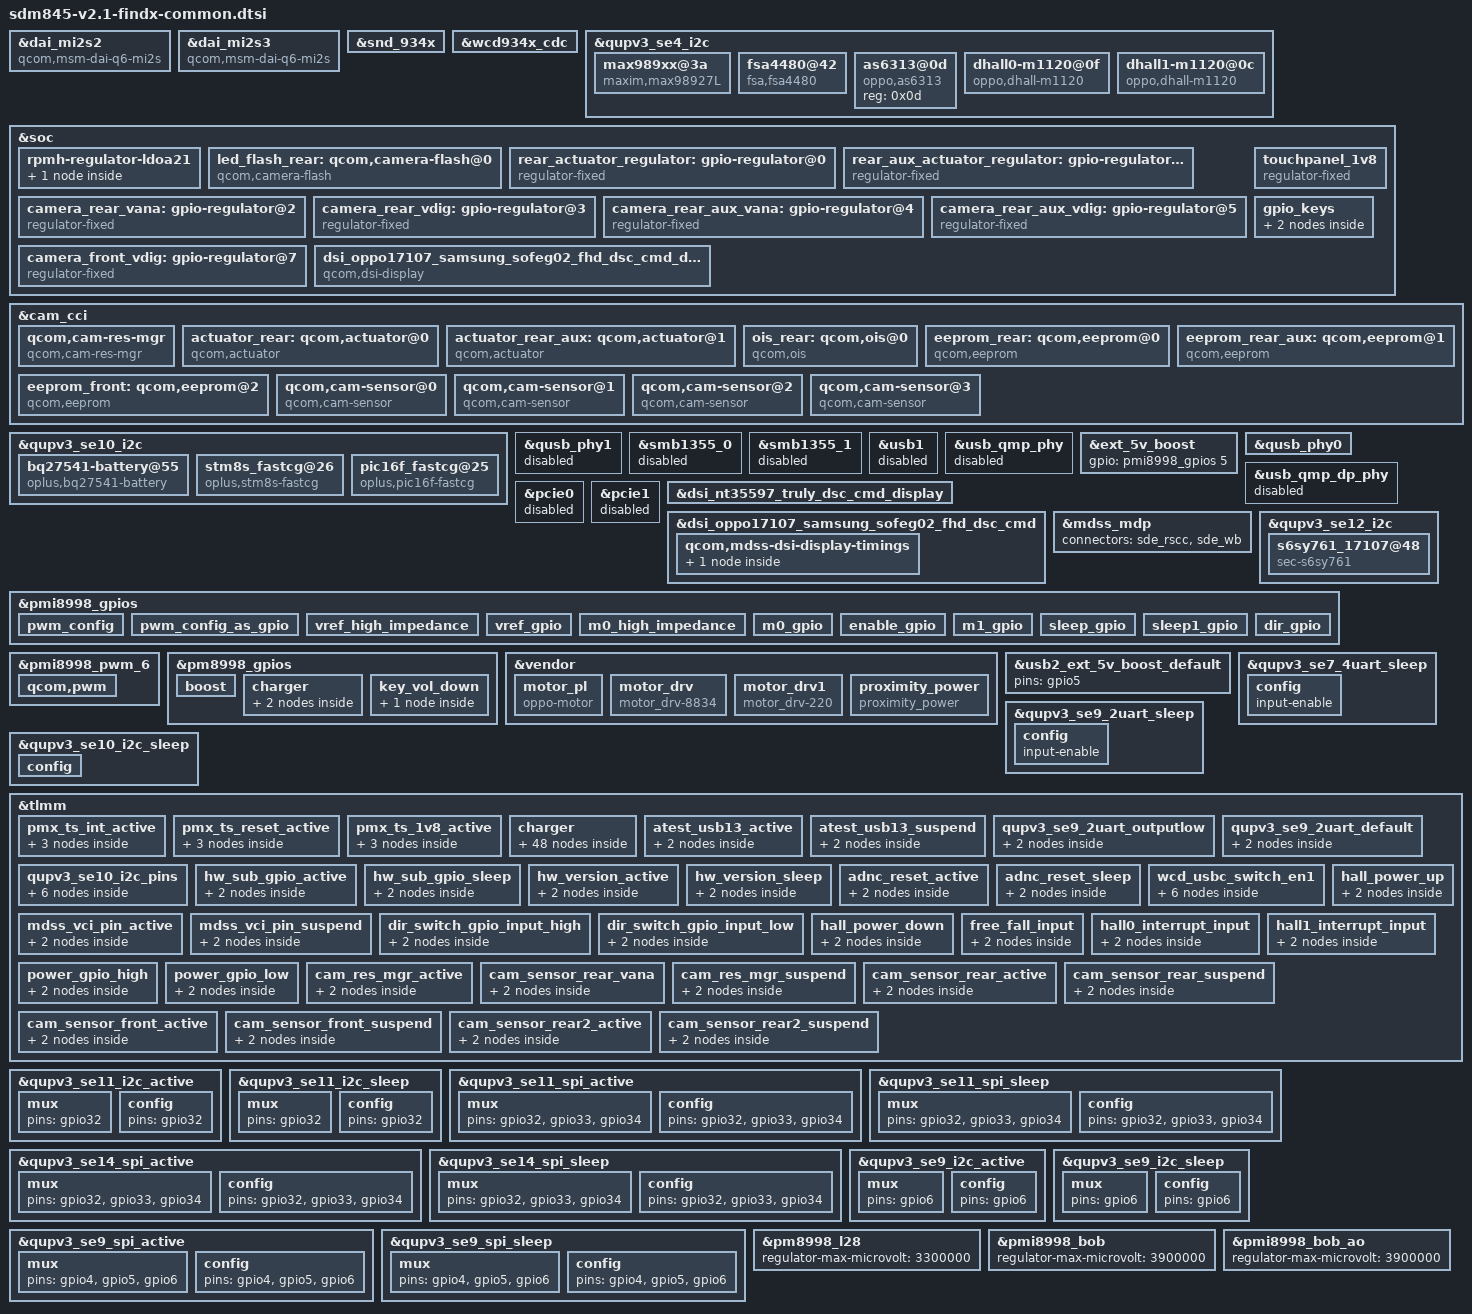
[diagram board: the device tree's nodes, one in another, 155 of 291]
/* Copyright (c) 2016-2017, The Linux Foundation. All rights reserved.
 *
 * This program is free software; you can redistribute it and/or modify
 * it under the terms of the GNU General Public License version 2 and
 * only version 2 as published by the Free Software Foundation.
 *
 * This program is distributed in the hope that it will be useful,
 * but WITHOUT ANY WARRANTY; without even the implied warranty of
 * MERCHANTABILITY or FITNESS FOR A PARTICULAR PURPOSE.  See the
 * GNU General Public License for more details.
 */

#include "dsi-panel-dsi_oppo17107_samsung_sofeg02_fhd_dsc_cmd.dtsi"

/* Audio */
&dai_mi2s2 {
    compatible = "qcom,msm-dai-q6-mi2s";
    qcom,msm-dai-q6-mi2s-dev-id = <2>;
    qcom,msm-mi2s-rx-lines = <2>;
    qcom,msm-mi2s-tx-lines = <1>;
    pinctrl-names = "default", "sleep";
    pinctrl-0 = <&tert_mi2s_active
            &tert_mi2s_sd0_active
            &tert_mi2s_sd1_active>;
    pinctrl-1 = <&tert_mi2s_sleep
            &tert_mi2s_sd0_sleep
            &tert_mi2s_sd1_sleep>;
};

&dai_mi2s3 {
    compatible = "qcom,msm-dai-q6-mi2s";
    qcom,msm-dai-q6-mi2s-dev-id = <3>;
    qcom,msm-mi2s-rx-lines = <2>;
    qcom,msm-mi2s-tx-lines = <1>;
    pinctrl-names = "default", "sleep";
    pinctrl-0 = <&quat_mi2s_active
            &quat_mi2s_sd0_active
            &quat_mi2s_sd1_active>;
    pinctrl-1 = <&quat_mi2s_sleep
            &quat_mi2s_sd0_sleep
            &quat_mi2s_sd1_sleep>;
};

&snd_934x {
	qcom,msm-mbhc-hs-mic-max-threshold-mv = <2600>;
	qcom,msm-mbhc-hs-mic-min-threshold-mv = <75>;
};

&wcd934x_cdc {
    qcom,cdc-micbias1-mv = <1800>;
    qcom,cdc-micbias2-mv = <2700>;
    qcom,cdc-micbias3-mv = <1800>;
    qcom,cdc-micbias4-mv = <2850>;
};

&qupv3_se4_i2c {
	status = "ok";

	max989xx@3a {
		compatible = "maxim,max98927L";
		reg = <0x3a>;
		mono_stereo_mode = <0>;
		interleave_mode = <0>;
		maxim,98927-reset-gpio = <&tlmm 69 0x00>;
		max989xx_vdd-supply = <&pm8998_s4>;
		status = "okay";
	};
};

&qupv3_se4_i2c {
	status = "ok";
	fsa4480@42 {
		compatible = "fsa,fsa4480";
		reg = <0x42>;
		interrupts = <52 0>;
		oppo,fsa4480-irq = <&tlmm 52 0x00>;
		interrupt-names = "fsa4480_irq";
		status = "okay";
	};
};

&qupv3_se4_i2c {
	status = "ok";
	as6313@0d {
		compatible = "oppo,as6313";
		reg = <0x0d>;
		status = "okay";
	};
};

/* Camera */
&soc {
	/delete-node/ qupv3_se2_i2c;
	/delete-node/ qupv3_se2_spi;

	rpmh-regulator-ldoa21 {
		pm8998_l21: regulator-l21 {
			regulator-min-microvolt = <2850000>;
		};
	};

	led_flash_rear: qcom,camera-flash@0 {
		cell-index = <0>;
		reg = <0x00 0x00>;
		compatible = "qcom,camera-flash";
		qcom,flash-name = "pmic";
		flash-source = <&pmi8998_flash0>;
		torch-source = <&pmi8998_torch0>;
		switch-source = <&pmi8998_switch0>;
		status = "ok";
	};

	rear_actuator_regulator: gpio-regulator@0 {
		compatible = "regulator-fixed";
		reg = <0x00 0x00>;
		regulator-name = "rear_actuator_regulator";
		regulator-min-microvolt = <2800000>;
		regulator-max-microvolt = <2800000>;
		regulator-enable-ramp-delay = <100>;
		enable-active-high;
		vin-supply = <&pmi8998_bob>;
	};

	rear_aux_actuator_regulator: gpio-regulator@1 {
		compatible = "regulator-fixed";
		reg = <0x01 0x00>;
		regulator-name = "rear_aux_actuator_regulator";
		regulator-min-microvolt = <2800000>;
		regulator-max-microvolt = <2800000>;
		regulator-enable-ramp-delay = <100>;
		enable-active-high;
		vin-supply = <&pmi8998_bob>;
	};

	camera_rear_vana: gpio-regulator@2 {
		compatible = "regulator-fixed";
		reg = <0x02 0x00>;
		regulator-name = "camera_rear_vana";
		regulator-min-microvolt = <2800000>;
		regulator-max-microvolt = <2800000>;
		regulator-enable-ramp-delay = <135>;
		enable-active-high;
		gpio = <&tlmm 27 0>;
		pinctrl-names = "default";
		pinctrl-0 = <&cam_sensor_rear_vana>;
		vin-supply = <&pmi8998_bob>;
	};

	camera_rear_vdig: gpio-regulator@3 {
		compatible = "regulator-fixed";
		reg = <0x03 0x00>;
		regulator-name = "camera_rear_vdig";
		regulator-min-microvolt = <1050000>;
		regulator-max-microvolt = <1050000>;
		regulator-enable-ramp-delay = <135>;
		enable-active-high;
		gpio = <&tlmm 8 0>;
		vin-supply = <&pmi8998_bob &pm8998_s3>;
	};

	camera_rear_aux_vana: gpio-regulator@4 {
		compatible = "regulator-fixed";
		reg = <0x04 0x00>;
		regulator-name = "camera_rear_aux_vana";
		regulator-min-microvolt = <2800000>;
		regulator-max-microvolt = <2800000>;
		regulator-enable-ramp-delay = <135>;
		enable-active-high;
		gpio = <&tlmm 82 0>;
		vin-supply = <&pmi8998_bob>;
	};

	camera_rear_aux_vdig: gpio-regulator@5 {
		compatible = "regulator-fixed";
		reg = <0x05 0x00>;
		regulator-name = "camera_rear_aux_vdig";
		regulator-min-microvolt = <1050000>;
		regulator-max-microvolt = <1050000>;
		regulator-enable-ramp-delay = <135>;
		enable-active-high;
		gpio = <&tlmm 79 0>;
		vin-supply = <&pmi8998_bob &pm8998_s3>;
	};

	camera_front_vdig: gpio-regulator@7 {
		compatible = "regulator-fixed";
		reg = <0x07 0x00>;
		regulator-name = "camera_front_vdig";
		regulator-min-microvolt = <1050000>;
		regulator-max-microvolt = <1050000>;
		regulator-enable-ramp-delay = <135>;
		enable-active-high;
		gpio = <&tlmm 117 0>;
		vin-supply = <&pmi8998_bob &pm8998_s3>;
	};
};

&cam_cci {
	qcom,cam-res-mgr {
		compatible = "qcom,cam-res-mgr";
		status = "ok";
		shared-gpios = <122 8>;
		pinctrl-names = "cam_res_mgr_default", "cam_res_mgr_suspend";
		pinctrl-0 = <&cam_res_mgr_active>;
		pinctrl-1 = <&cam_res_mgr_suspend>;
	};

	actuator_rear: qcom,actuator@0 {
		cell-index = <0>;
		reg = <0x0>;
		compatible = "qcom,actuator";
		cci-master = <0>;
		cam_vaf-supply = <&rear_actuator_regulator>;
		regulator-names = "cam_vaf";
		rgltr-cntrl-support;
		rgltr-min-voltage = <2800000>;
		rgltr-max-voltage = <2800000>;
		rgltr-load-current = <0>;
		gpios = <&tlmm 122 0>;
		gpio-vaf = <0>;
		gpio-req-tbl-num = <0>;
		gpio-req-tbl-flags = <0>;
		gpio-req-tbl-label = "CAM_VAF";
	};

	actuator_rear_aux: qcom,actuator@1 {
		cell-index = <1>;
		reg = <0x1>;
		compatible = "qcom,actuator";
		cci-master = <1>;
		cam_vaf-supply = <&rear_aux_actuator_regulator>;
		regulator-names = "cam_vaf";
		rgltr-cntrl-support;
		rgltr-min-voltage = <2800000>;
		rgltr-max-voltage = <2800000>;
		rgltr-load-current = <0>;
		gpios = <&tlmm 122 0>;
		gpio-vaf = <0>;
		gpio-req-tbl-num = <0>;
		gpio-req-tbl-flags = <0>;
		gpio-req-tbl-label = "CAM_VAF";
	};

	ois_rear: qcom,ois@0 {
		cell-index = <0>;
		reg = <0x0>;
		compatible = "qcom,ois";
		cci-master = <0>;
		status = "ok";
	};

	eeprom_rear: qcom,eeprom@0 {
		cell-index = <0>;
		reg = <0>;
		compatible = "qcom,eeprom";
		cam_vana-supply = <&camera_rear_vana>;
		cam_vdig-supply = <&camera_rear_vdig>;
		//cam_vio-supply = <&pm8998_lvs1>;
		cam_clk-supply = <&titan_top_gdsc>;
		regulator-names = "cam_clk", "cam_vana", "cam_vdig";
		rgltr-cntrl-support;
		rgltr-min-voltage = <0 2800000 1050000>;
		rgltr-max-voltage = <0 2800000 1050000>;
		rgltr-load-current = <0 0 0>;
		gpio-no-mux = <0>;
		pinctrl-names = "cam_default", "cam_suspend";
		pinctrl-0 = <&cam_sensor_mclk0_active
				&cam_sensor_rear_active>;
		pinctrl-1 = <&cam_sensor_mclk0_suspend
				&cam_sensor_rear_suspend>;
		gpios = <&tlmm 13 0>,
			<&tlmm 28 0>;
		gpio-reset = <1>;
		gpio-req-tbl-num = <0 1>;
		gpio-req-tbl-flags = <1 0>;
		gpio-req-tbl-label = "CAMIF_MCLK0",
					"CAM_RESET0";
		sensor-position = <0>;
		sensor-mode = <0>;
		cci-master = <0>;
		status = "ok";
		clocks = <&clock_camcc CAM_CC_MCLK0_CLK>;
		clock-names = "cam_clk";
		clock-cntl-level = "turbo";
		clock-rates = <24000000>;
	};

	eeprom_rear_aux: qcom,eeprom@1 {
		cell-index = <1>;
		reg = <0x1>;
		compatible = "qcom,eeprom";
		cam_vana-supply = <&camera_rear_aux_vana>;
		cam_vdig-supply = <&camera_rear_aux_vdig>;
		//cam_vio-supply = <&pm8998_lvs1>;
		cam_clk-supply = <&titan_top_gdsc>;
		regulator-names = "cam_clk", "cam_vana", "cam_vdig";
		rgltr-cntrl-support;
		rgltr-min-voltage = <0 2800000 1050000>;
		rgltr-max-voltage = <0 2800000 1050000>;
		rgltr-load-current = <0 0 0>;
		gpio-no-mux = <0>;
		pinctrl-names = "cam_default", "cam_suspend";
		pinctrl-0 = <&cam_sensor_mclk2_active
				 &cam_sensor_rear2_active>;
		pinctrl-1 = <&cam_sensor_mclk2_suspend
				 &cam_sensor_rear2_suspend>;
		gpios = <&tlmm 15 0>,
			<&tlmm 23 0>;
		gpio-reset = <1>;
		gpio-req-tbl-num = <0 1>;
		gpio-req-tbl-flags = <1 0>;
		gpio-req-tbl-label = "CAMIF_MCLK1",
					"CAM_RESET1";
		sensor-position = <0>;
		sensor-mode = <0>;
		cci-master = <1>;
		status = "ok";
		clocks = <&clock_camcc CAM_CC_MCLK2_CLK>;
		clock-names = "cam_clk";
		clock-cntl-level = "turbo";
		clock-rates = <24000000>;
	};

	eeprom_front: qcom,eeprom@2 {
		cell-index = <2>;
		reg = <0x2>;
		compatible = "qcom,eeprom";
		cam_vana-supply = <&camera_rear_vana>;
		cam_vdig-supply = <&camera_front_vdig>;
		//cam_vio-supply = <&pm8998_lvs1>;
		cam_clk-supply = <&titan_top_gdsc>;
		regulator-names = "cam_clk", "cam_vana", "cam_vdig";
		rgltr-cntrl-support;
		rgltr-min-voltage = <0 2800000 1050000>;
		rgltr-max-voltage = <0 2800000 1050000>;
		rgltr-load-current = <0 0 0>;
		gpio-no-mux = <0>;
		pinctrl-names = "cam_default", "cam_suspend";
		pinctrl-0 = <&cam_sensor_mclk1_active
				 &cam_sensor_front_active>;
		pinctrl-1 = <&cam_sensor_mclk1_suspend
				 &cam_sensor_front_suspend>;
		gpios = <&tlmm 14 0>,
			<&tlmm 9 0>;
		gpio-reset = <1>;
		gpio-req-tbl-num = <0 1>;
		gpio-req-tbl-flags = <1 0>;
		gpio-req-tbl-label = "CAMIF_MCLK2",
					"CAM_RESET2";
		sensor-position = <1>;
		sensor-mode = <0>;
		cci-master = <0>;
		status = "ok";
		clocks = <&clock_camcc CAM_CC_MCLK1_CLK>;
		clock-names = "cam_clk";
		clock-cntl-level = "turbo";
		clock-rates = <24000000>;
	};

	qcom,cam-sensor@0 {
		cell-index = <0>;
		compatible = "qcom,cam-sensor";
		reg = <0x0>;
		csiphy-sd-index = <0>;
		sensor-position-roll = <270>;
		sensor-position-pitch = <0>;
		sensor-position-yaw = <180>;
		led-flash-src = <&led_flash_rear>;
		actuator-src = <&actuator_rear>;
		ois-src = <&ois_rear>;
		eeprom-src = <&eeprom_rear>;
		cam_vana-supply = <&camera_rear_vana>;
		cam_vdig-supply = <&camera_rear_vdig>;
		//cam_vio-supply = <&pm8998_lvs1>;
		cam_v_custom1-supply = <&pm8998_l21>;
		cam_clk-supply = <&titan_top_gdsc>;
		regulator-names = "cam_clk", "cam_vana", "cam_vdig", "cam_v_custom1";
		rgltr-cntrl-support;
		rgltr-min-voltage = <0 2800000 1050000 2850000>;
		rgltr-max-voltage = <0 2800000 1050000 2850000>;
		rgltr-load-current = <0 0 0 800000>;
		gpio-no-mux = <0>;
		pinctrl-names = "cam_default", "cam_suspend";
		pinctrl-0 = <&cam_sensor_mclk0_active
				&cam_sensor_rear_active>;
		pinctrl-1 = <&cam_sensor_mclk0_suspend
				&cam_sensor_rear_suspend>;
		gpios = <&tlmm 13 0>,
			<&tlmm 28 0>;
		gpio-reset = <1>;
		gpio-req-tbl-num = <0 1>;
		gpio-req-tbl-flags = <1 0>;
		gpio-req-tbl-label = "CAMIF_MCLK0",
					"CAM_RESET0";
		sensor-mode = <0>;
		cci-master = <0>;
		status = "ok";
		clocks = <&clock_camcc CAM_CC_MCLK0_CLK>;
		clock-names = "cam_clk";
		clock-cntl-level = "turbo";
		clock-rates = <24000000>;
	};

	qcom,cam-sensor@1 {
		cell-index = <1>;
		compatible = "qcom,cam-sensor";
		reg = <0x1>;
		csiphy-sd-index = <1>;
		sensor-position-roll = <270>;
		sensor-position-pitch = <0>;
		sensor-position-yaw = <180>;
		actuator-src = <&actuator_rear_aux>;
		led-flash-src = <&led_flash_rear>;
		eeprom-src = <&eeprom_rear_aux>;
		cam_vana-supply = <&camera_rear_aux_vana>;
		cam_vdig-supply = <&camera_rear_aux_vdig>;
		//cam_vio-supply = <&pm8998_lvs1>;
		cam_clk-supply = <&titan_top_gdsc>;
		regulator-names = "cam_clk", "cam_vana", "cam_vdig";
		rgltr-cntrl-support;
		rgltr-min-voltage = <0 2800000 1050000>;
		rgltr-max-voltage = <0 2800000 1050000>;
		rgltr-load-current = <0 0 0>;
		gpio-no-mux = <0>;
		pinctrl-names = "cam_default", "cam_suspend";
		pinctrl-0 = <&cam_sensor_mclk2_active
				&cam_sensor_rear2_active>;
		pinctrl-1 = <&cam_sensor_mclk2_suspend
				&cam_sensor_rear2_suspend>;
		gpios = <&tlmm 15 0>,
			<&tlmm 23 0>;
		gpio-reset = <1>;
		gpio-req-tbl-num = <0 1>;
		gpio-req-tbl-flags = <1 0>;
		gpio-req-tbl-label = "CAMIF_MCLK1",
					"CAM_RESET1";
		sensor-mode = <0>;
		cci-master = <1>;
		status = "ok";
		clocks = <&clock_camcc CAM_CC_MCLK2_CLK>;
		clock-names = "cam_clk";
		clock-cntl-level = "turbo";
		clock-rates = <24000000>;
	};

	qcom,cam-sensor@2 {
		cell-index = <2>;
		compatible = "qcom,cam-sensor";
		reg = <0x02>;
		csiphy-sd-index = <2>;
		sensor-position-roll = <270>;
		sensor-position-pitch = <0>;
		sensor-position-yaw = <0>;
		eeprom-src = <&eeprom_front>;
		/*
		actuator-src = <&actuator_front>;
		led-flash-src = <&led_flash_front>;
		*/
		cam_vana-supply = <&camera_rear_vana>;
		cam_vdig-supply = <&camera_front_vdig>;
		//cam_vio-supply = <&pm8998_lvs1>;
		cam_clk-supply = <&titan_top_gdsc>;
		regulator-names = "cam_clk", "cam_vana", "cam_vdig";
		rgltr-cntrl-support;
		rgltr-min-voltage = <0 2800000 1050000>;
		rgltr-max-voltage = <0 2800000 1050000>;
		rgltr-load-current = <0 0 0>;
		gpio-no-mux = <0>;
		pinctrl-names = "cam_default", "cam_suspend";
		pinctrl-0 = <&cam_sensor_mclk1_active
				 &cam_sensor_front_active>;
		pinctrl-1 = <&cam_sensor_mclk1_suspend
				 &cam_sensor_front_suspend>;
		gpios = <&tlmm 14 0>,
			<&tlmm 9 0>;
		gpio-reset = <1>;
		gpio-req-tbl-num = <0 1>;
		gpio-req-tbl-flags = <1 0>;
		gpio-req-tbl-label = "CAMIF_MCLK2",
					"CAM_RESET2";
		sensor-mode = <0>;
		cci-master = <0>;
		status = "ok";
		clocks = <&clock_camcc CAM_CC_MCLK1_CLK>;
		clock-names = "cam_clk";
		clock-cntl-level = "turbo";
		clock-rates = <24000000>;
	};

	qcom,cam-sensor@3 {
		cell-index = <3>;
		compatible = "qcom,cam-sensor";
		reg = <0x03>;
		csiphy-sd-index = <3>;
		sensor-position-roll = <270>;
		sensor-position-pitch = <0>;
		sensor-position-yaw = <0>;
		gpio-no-mux = <0>;
		sensor-mode = <0>;
		cci-master = <1>;
		status = "ok";
	};
};

/* Charger */
&qupv3_se10_i2c {
	pinctrl-names = "default", "sleep", "pulldown", "pullup";
	pinctrl-2 = <&qupv3_se10_i2c_pulldown>;
	pinctrl-3 = <&qupv3_se10_i2c_pullup>;

	bq27541-battery@55 {
		status = "okay";
		compatible = "oplus,bq27541-battery";
		reg = <0x55>;
		qcom,modify-soc-smooth;
	};

	stm8s_fastcg@26{
		status = "okay";
		compatible = "oplus,stm8s-fastcg";
		reg = <0x26>;
		qcom,oplus_batt_4400mv;
		qcom,vooc_fw_update_newmethod;
		qcom,vooc-fw-type = <5>;
		qcom,vooc-low-temp = <120>;
		qcom,vooc-high-temp = <430>;
		qcom,vooc-low-soc = <1>;
		qcom,vooc-high-soc = <85>;

		pinctrl-names = "switch1_act_switch2_act", "switch1_sleep_switch2_sleep",
						"switch1_act_switch3_act", "switch1_sleep_switch3_sleep",
						"switch1_act_switch2_sleep", "switch1_sleep_switch2_act",
						"clock_active","clock_sleep",
						"data_active","data_sleep",
						"reset_active","reset_sleep";
		pinctrl-0 = <&charging_switch1_active>;
		pinctrl-1 = <&charging_switch1_sleep >;
		pinctrl-2 = <&charging_switch1_active>;
		pinctrl-3 = <&charging_switch1_sleep >;
		pinctrl-4 = <&charging_switch1_active>;
		pinctrl-5 = <&charging_switch1_sleep>;
		pinctrl-6 = <&charging_clock_active >;
		pinctrl-7 = <&charging_clock_sleep >;
		pinctrl-8 = <&charging_data_active >;
		pinctrl-9 = <&charging_data_sleep >;
		pinctrl-10 = <&charging_reset_active >;
		pinctrl-11 = <&charging_reset_sleep >;

		qcom,charging_switch1-gpio = <&tlmm 51 0x00>;
		//qcom,charging_switch2-gpio = <&tlmm 113 0x00>;
		//qcom,charging_switch3-gpio = <&tlmm 38 0x00>;

		qcom,charging_reset-gpio = <&tlmm 102 0x00>;
		qcom,charging_clock-gpio = <&tlmm 43 0x00>;
		qcom,charging_data-gpio = <&tlmm 44 0x00>;
	};

	pic16f_fastcg@25{
		status = "okay";
		compatible = "oplus,pic16f-fastcg";
		reg = <0x25>;

		pinctrl-names = "switch1_act_switch2_act", "switch1_sleep_switch2_sleep",
						"switch1_act_switch3_act", "switch1_sleep_switch3_sleep",
						"switch1_act_switch2_sleep", "switch1_sleep_switch2_act",
						"clock_active","clock_sleep",
						"data_active","data_sleep",
						"reset_active","reset_sleep";
		pinctrl-0 = <&charging_switch1_active>;
		pinctrl-1 = <&charging_switch1_sleep >;
		pinctrl-2 = <&charging_switch1_active>;
		pinctrl-3 = <&charging_switch1_sleep >;
		pinctrl-4 = <&charging_switch1_active>;
		pinctrl-5 = <&charging_switch1_sleep>;
		pinctrl-6 = <&charging_clock_active >;
		pinctrl-7 = <&charging_clock_sleep >;
		pinctrl-8 = <&charging_data_active >;
		pinctrl-9 = <&charging_data_sleep >;
		pinctrl-10 = <&charging_reset_active >;
		pinctrl-11 = <&charging_reset_sleep >;

		qcom,charging_switch1-gpio = <&tlmm 51 0x00>;
		//qcom,charging_switch2-gpio = <&tlmm 113 0x00>;
		//qcom,charging_switch3-gpio = <&tlmm 38 0x00>;

		qcom,charging_reset-gpio = <&tlmm 102 0x00>;
		qcom,charging_clock-gpio = <&tlmm 43 0x00>;
		qcom,charging_data-gpio = <&tlmm 44 0x00>;
	};
};

&qusb_phy1 {
	status = "disabled";
};

&smb1355_0 {
	status = "disabled";
};

&smb1355_1 {
	status = "disabled";
};

&usb1 {
	status = "disabled";
};

&usb_qmp_phy {
	status = "disabled";
};

&ext_5v_boost {
	gpio = <&pmi8998_gpios 5 GPIO_ACTIVE_HIGH>;
};

&qusb_phy0 {
	qcom,qusb-phy-init-seq =
		/* <value reg_offset> */
		<0x23 0x210 /* PWR_CTRL1 */
		0x03 0x04  /* PLL_ANALOG_CONTROLS_TWO */
		0x7c 0x18c /* PLL_CLOCK_INVERTERS */
		0x80 0x2c  /* PLL_CMODE */
		0x0a 0x184 /* PLL_LOCK_DELAY */
		0x19 0xb4  /* PLL_DIGITAL_TIMERS_TWO */
		0x40 0x194 /* PLL_BIAS_CONTROL_1 */
		//0x20 0x198 /* PLL_BIAS_CONTROL_2 */
		0x1e 0x198 /* PLL_BIAS_CONTROL_2 */
		0x21 0x214 /* PWR_CTRL2 */
		0x08 0x220 /* IMP_CTRL1 */
		0x58 0x224 /* IMP_CTRL2 */
		//0x45 0x240 /* TUNE1 */
		0x42 0x240 /* TUNE1 */
		0x29 0x244 /* TUNE2 */
		0xca 0x248 /* TUNE3 */
		0x04 0x24c /* TUNE4 */
		0x03 0x250 /* TUNE5 */
		0x00 0x23c /* CHG_CTRL2 */
		0x22 0x210>; /* PWR_CTRL1 */
	qcom,qusb-phy-init-seq-new =
		/* <value reg_offset> */
		<0x23 0x210 /* PWR_CTRL1 */
		0x03 0x04  /* PLL_ANALOG_CONTROLS_TWO */
		0x7c 0x18c /* PLL_CLOCK_INVERTERS */
		0x80 0x2c  /* PLL_CMODE */
		0x0a 0x184 /* PLL_LOCK_DELAY */
		0x19 0xb4  /* PLL_DIGITAL_TIMERS_TWO */
		0x40 0x194 /* PLL_BIAS_CONTROL_1 */
		//0x20 0x198 /* PLL_BIAS_CONTROL_2 */
		0x1a 0x198 /* PLL_BIAS_CONTROL_2 */
		0x21 0x214 /* PWR_CTRL2 */
		0x08 0x220 /* IMP_CTRL1 */
		0x58 0x224 /* IMP_CTRL2 */
		//0x45 0x240 /* TUNE1 */
		0x43 0x240 /* TUNE1 */
		0x29 0x244 /* TUNE2 */
		0xca 0x248 /* TUNE3 */
		0x04 0x24c /* TUNE4 */
		0x03 0x250 /* TUNE5 */
		0x00 0x23c /* CHG_CTRL2 */
		0x22 0x210>; /* PWR_CTRL1 */
	qcom,qusb-phy-oppo-host-init-seq =
		/* <value reg_offset> */
		<0x23 0x210 /* PWR_CTRL1 */
		0x03 0x04  /* PLL_ANALOG_CONTROLS_TWO */
		0x7c 0x18c /* PLL_CLOCK_INVERTERS */
		0x80 0x2c  /* PLL_CMODE */
		0x0a 0x184 /* PLL_LOCK_DELAY */
		0x19 0xb4  /* PLL_DIGITAL_TIMERS_TWO */
		0x40 0x194 /* PLL_BIAS_CONTROL_1 */
		0x1e 0x198 /* PLL_BIAS_CONTROL_2 */
		0x21 0x214 /* PWR_CTRL2 */
		0x07 0x220 /* IMP_CTRL1 */
		0x58 0x224 /* IMP_CTRL2 */
		0x46 0x240 /* TUNE1 */
		0x2b 0x244 /* TUNE2 */
		0xca 0x248 /* TUNE3 */
		0x04 0x24c /* TUNE4 */
		0x03 0x250 /* TUNE5 */
		0x00 0x23c /* CHG_CTRL2 */
		0x22 0x210>; /* PWR_CTRL1 */
};

&usb_qmp_dp_phy {
	status = "disabled";
};

&pcie0 {
	status = "disabled";
};

&pcie1 {
	status = "disabled";
};

/* Display */
&dsi_nt35597_truly_dsc_cmd_display {
	/delete-property/ qcom,dsi-display-active;
};

&dsi_oppo17107_samsung_sofeg02_fhd_dsc_cmd{
	qcom,dsi-display-active;
};

&dsi_oppo17107_samsung_sofeg02_fhd_dsc_cmd{
	qcom,panel-supply-entries = <&dsi_panel_pwr_supply_no_labibb>;
	qcom,panel-supply-oppo-hardware-march = <&dsi_panel_pwr_supply_vdd_no_labibb>;

	qcom,mdss-dsi-bl-min-level = <1>;
	qcom,mdss-dsi-mode-sel-gpio-state = "single_port";
	qcom,panel-mode-gpio = <&tlmm 52 0>;
	qcom,platform-te-gpio = <&tlmm 10 0>;
	qcom,platform-reset-gpio = <&tlmm 6 0>;
	qcom,platform-vci-control-gpio = <&tlmm 26 0>;
};

&mdss_mdp {
	connectors = <&sde_rscc &sde_wb>;
};

&dsi_oppo17107_samsung_sofeg02_fhd_dsc_cmd {
	qcom,mdss-dsi-t-clk-post = <0x11>;
	qcom,mdss-dsi-t-clk-pre =  <0x34>;
	qcom,mdss-dsi-display-timings {
		timing@0{
			qcom,mdss-dsi-panel-phy-timings = [00 14 05 05 1F 0A 05
				05 03 03 04 00];
			qcom,display-topology = <1 1 1>,
						<2 2 1>, /* dsc merge */
						<2 1 1>; /* 3d mux */
			qcom,default-topology-index = <1>;
		};
	};
};

&soc {
	dsi_oppo17107_samsung_sofeg02_fhd_dsc_cmd_display: qcom,dsi-display@1 {
		compatible = "qcom,dsi-display";
		label = "dsi_oppo17107_samsung_sofeg02_fhd_dsc_cmd_display";
		qcom,display-type = "primary";

		qcom,dsi-ctrl = <&mdss_dsi0>;
		qcom,dsi-phy = <&mdss_dsi_phy0>;
		clocks = <&mdss_dsi0_pll BYTECLK_MUX_0_CLK>,
			<&mdss_dsi0_pll PCLK_MUX_0_CLK>;
		clock-names = "mux_byte_clk", "mux_pixel_clk";

		pinctrl-names = "panel_active", "panel_suspend";
		pinctrl-0 = <&sde_dsi_active &sde_te_active  &mdss_vci_pin_active>;
		pinctrl-1 = <&sde_dsi_suspend &sde_te_suspend  &mdss_vci_pin_suspend>;
		qcom,platform-te-gpio = <&tlmm 10 0>;
		qcom,platform-reset-gpio = <&tlmm 6 0>;
		qcom,platform-vci-control-gpio = <&tlmm 26 0>;
		//qcom,platform-poc-control-gpio = <&tlmm 25 0>;

		qcom,dsi-panel = <&dsi_oppo17107_samsung_sofeg02_fhd_dsc_cmd>;

		vddio-supply = <&pm8998_l14>;
		vdd-supply = <&pm8998_l28>;
	};
};

/* Touchscreen */
&qupv3_se12_i2c {
	status = "okay";
	s6sy761_17107@48 {
		compatible = "sec-s6sy761";
		reg = <0x48>;
		chip-name = "S6SY761";

		/* Interrupt && Irq-gpio */
		interrupt-parent = <&tlmm>;
		interrupts = <125 0x2008>;

		/* Power Config */
		enable2v8_gpio = <&tlmm 26 0x1>;
		// enable1v8_gpio = <&tlmm 32 0x1>;
		vdd_2v8-supply = <&pm8998_l28>;
		vcc_1v8-supply = <&touchpanel_1v8>;
		vdd_2v8_volt = <3300000>;

		/* Other HW Resource */
		irq-gpio = <&tlmm 125 0x2008>;
		reset-gpio = <&tlmm 99 0x1>;
		pinctrl-names = "default";
		pinctrl-0 = <&ts_int_active &ts_reset_active &ts_1v8_active>;

		touchpanel,max-num-support = <10>;
		touchpanel,tx-rx-num = <17 37>;
		earsense,tx-rx-num = <17 18>;
		touchpanel,panel-coords = <1080 2340>;
		touchpanel,display-coords = <1080 2340>;
		touchpanel,touchmajor-limit = <32 54>;

		/* SW Support Feature Control */
		ear_sense_support;
		black_gesture_support;
		fw_edge_limit_support;
		charger_pump_support;
		// spurious_fingerprint_support;
		fw_update_app_support;
		smart_gesture_support;
		game_switch_support;
		kernel_grip_support_special;
		auto_test_need_cal_support;

		/*
		 * Virtual Key Config:
		 * 1:touchpanel,button-type: <virtualkey_type  supportted_button-map>
		 * virtualkey_type:
		 * Type 1: using board_properties
		 * Type 2: using same IC (button zone&& touch zone are seprate)
		 * Type 3: using diffrent IC (button zone&& touch zone are seprate)
		 * Type 4: No need of virtual key process
		 * supportted_button-map:select|menu|home|back
		 *
		 * 2:touchpanel,button-map
		 * type (X1,Y1)(X2,Y2)(X3,Y3)(Width_X,Hight_Y)--Only when button-type is 0
		 */
		touchpanel,button-type = <4>;
		touchpanel.button-TRx = <0 0>;
	};
};

&soc {
	touchpanel_1v8: touchpanel_1v8 {
		compatible = "regulator-fixed";
		regulator-name = "touchpanel_1v8";
		startup-delay-us = <0>;
		enable-active-high;
		gpio = <&tlmm 32 0>;
	};
};

/* Motor */
&qupv3_se4_i2c {
	status = "okay";
	dhall0-m1120@0f {
		compatible = "oppo,dhall-m1120";
		reg = <0x0c>;
		pinctrl-names = "hall_power_down","hall_power_up","hall0_interrupt_input";
		pinctrl-0 = <&hall_power_down>;
		pinctrl-1 = <&hall_power_up>;
		pinctrl-2 = <&hall0_interrupt_input>;
		interrupt-parent = <&tlmm>;
		interrupts = <124 0x2>;
		dhall,irq-gpio = <&tlmm 124 0x2008>;
		dhall,id = <0>;
		vdd_2v8-supply = <&pm8998_l19>; // VREG_L19A_3P0
		vcc_1v8-supply = <&pm8998_s4>; // VREG_S4A_1P8
		qcom,hall-power-gpio = <&tlmm 21 0>;
	};

	dhall1-m1120@0c {
		compatible = "oppo,dhall-m1120";
		reg = <0x0f>;
		pinctrl-names = "hall_power_down","hall_power_up","hall1_interrupt_input";
		pinctrl-0 = <&hall_power_down>;
		pinctrl-1 = <&hall_power_up>;
		pinctrl-2 = <&hall1_interrupt_input>;
		interrupt-parent = <&tlmm>;
		interrupts = <92 0x2>;
		dhall,irq-gpio = <&tlmm 92 0x2008>;
		dhall,id = <1>;
		vdd_2v8-supply = <&pm8998_l19>; // VREG_L19A_3P0
		vcc_1v8-supply = <&pm8998_s4>; // VREG_S4A_1P8
		qcom,hall-power-gpio = <&tlmm 21 0>;
	};
};
&pmi8998_gpios {
	pwm_config: pwm_config {
		pins = "gpio8"; // GPIO 8
		function = "func1"; // Special Function 1,pwm
		bias-disable; // No Pull
		power-source = <0>;// VIN0
		output-low; // digital output, no invert
		qcom,drive-strength = <3>; // LOW strength
		drive-push-pull; // CMOS
	};

	pwm_config_as_gpio: pwm_config_as_gpio {
		pins = "gpio8"; // GPIO 8
		function = "normal";
		bias-disable; // No Pull
		power-source = <0>; // VIN0
		output-low; // digital output, no invert
		qcom,drive-strength = <3>; // LOW strength
		drive-push-pull; // CMOS
	};

	vref_high_impedance: vref_high_impedance {
		pins = "gpio10";
		function = "normal";
		bias-disable; /* No Pull */
		power-source = <0>; /* VIN0 1.8V*/
		output-low; /* digital output, no invert */
		qcom,drive-strength = <1>; /* high strength */
		drive-push-pull; /* CMOS */
		bias-high-impedance; // high_impedance mode
	};

	vref_gpio: vref_gpio {
		pins = "gpio10";
		function = "normal";
		bias-disable; /* No Pull */
		power-source = <0>; /* VIN0 1.8V*/
		output-low; /* digital output, no invert */
		qcom,drive-strength = <1>; /* high strength */
		drive-push-pull; /* CMOS */
	};

	m0_high_impedance: m0_high_impedance {
		pins = "gpio3";
		function = "normal";
		bias-disable; /* No Pull */
		power-source = <0>; /* VIN0 3.6V*/
		output-low; /* digital output, no invert */
		qcom,drive-strength = <3>; /* LOW strength */
		drive-push-pull; /* CMOS */
		bias-high-impedance; // high_impedance mode
	};

	m0_gpio: m0_gpio {
		pins = "gpio3";
		function = "normal";
		bias-disable; /* No Pull */
		power-source = <0>; /* VIN0 3.6V*/
		output-low; /* digital output, no invert */
		qcom,drive-strength = <3>; /* LOW strength */
		drive-push-pull; /* CMOS */
	};

	enable_gpio: enable_gpio {
		pins = "gpio3";
		function = "normal";
		bias-disable; /* No Pull */
		power-source = <0>; /* VIN0 3.6V*/
		output-low; /* digital output, no invert */
		qcom,drive-strength = <3>; /* LOW strength */
		drive-push-pull; /* CMOS */
	};

	m1_gpio: m1_gpio {
		pins = "gpio11";
		function = "normal";
		bias-disable; /* No Pull */
		power-source = <0>; /* VIN0 3.6V*/
		output-low; /* digital output, no invert */
		qcom,drive-strength = <3>; /* LOW strength */
		drive-push-pull; /* CMOS */
	};

	sleep_gpio: sleep_gpio {
		pins = "gpio1";
		function = "normal";
		bias-disable; /* No Pull */
		power-source = <0>; /* VIN0 3.6V*/
		output-low; /* digital output, no invert */
		qcom,drive-strength = <3>; /* LOW strength */
		drive-push-pull; /* CMOS */
	};

	sleep1_gpio: sleep1_gpio {
		pins = "gpio7";
		function = "normal";
		bias-disable; /* No Pull */
		power-source = <0>; /* VIN0 3.6V*/
		output-low; /* digital output, no invert */
		qcom,drive-strength = <3>; /* LOW strength */
		drive-push-pull; /* CMOS */
	};

	dir_gpio: dir_gpio {
		pins = "gpio6";
		function = "normal";
		bias-disable; /* No Pull */
		power-source = <0>; /* VIN0 3.6V*/
		output-low; /* digital output, no invert */
		qcom,drive-strength = <3>; /* LOW strength */
		drive-push-pull; /* CMOS */
	};
};

&pmi8998_pwm_6 {
	qcom,ramp-index = <1>;
	// qcom,force-pwm-size = <9>;
	qcom,mode-select = <0>; /* PWM */
	qcom,period = <7>;
	#pwm-cells = <2>;
	status = "okay";
	qcom,pwm {
		qcom,duty = <3>;
		label = "pwm";
	};
};

&pm8998_gpios {
	boost: boost {
		pins = "gpio7";
		function = "normal";
		bias-pull-down; // pull down
		power-source = <0>; // VIN0,1.8V
		output-low; // digital output, no invert
		qcom,drive-strength = <3>; // 0.15
	};
};

&vendor  {
	motor_pl: motor_pl {
		compatible = "oppo-motor";
		interrupt-parent = <&tlmm>;
		interrupts = <120 0x2>;
		motor,irq-gpio = <&tlmm 120 0x2008>;
		pinctrl-names = "free_fall_input";
		pinctrl-0 = <&free_fall_input>;
	};
	motor_drv: motor_drv {
		compatible = "motor_drv-8834";
		pinctrl-names = "boost","pwm_config","vref_high_impedance","vref_gpio",
					"m0_high_impedance","m0_gpio","m1_gpio","sleep_gpio","dir_gpio","dir_switch_gpio_input_high","dir_switch_gpio_input_low";
		pinctrl-0 = <&boost>;
		pinctrl-1 = <&pwm_config>;
		pinctrl-2 = <&vref_high_impedance>;
		pinctrl-3 = <&vref_gpio>;
		pinctrl-4 = <&m0_high_impedance>;
		pinctrl-5 = <&m0_gpio>;
		pinctrl-6 = <&m1_gpio>;
		pinctrl-7 = <&sleep_gpio &sleep1_gpio>;
		pinctrl-8 = <&dir_gpio>;
		pinctrl-9 = <&dir_switch_gpio_input_high>;
		pinctrl-10 = <&dir_switch_gpio_input_low>;
		pwms = <&pmi8998_pwm_6 0 0>;
		qcom,boost-gpio = <&pm8998_gpios 7 0x00>;
		qcom,vref-gpio = <&pmi8998_gpios 10 0>;
		qcom,sleep-gpio = <&pmi8998_gpios 1 0>;
		qcom,sleep1-gpio = <&pmi8998_gpios 7 0>;
		qcom,dir-gpio = <&pmi8998_gpios 6 0>;
		qcom,m0-gpio = <&pmi8998_gpios 3 0>;
		qcom,m1-gpio = <&pmi8998_gpios 11 0>;
		qcom,step-gpio = <&pmi8998_gpios 8 0>;
		qcom,dir_switch-gpio = <&tlmm 129 0>;
	};

	motor_drv1: motor_drv1 {
		compatible = "motor_drv-220";
		pinctrl-names = "boost","pwm_config","sleep_gpio","dir_gpio","dir_switch_gpio_input_high","dir_switch_gpio_input_low","enable_gpio","pwm_config_as_gpio";
		pinctrl-0 = <&boost>;
		pinctrl-1 = <&pwm_config>;
		pinctrl-2 = <&sleep_gpio &sleep1_gpio>;
		pinctrl-3 = <&dir_gpio>;
		pinctrl-4 = <&dir_switch_gpio_input_high>;
		pinctrl-5 = <&dir_switch_gpio_input_low>;
		pinctrl-6 = <&enable_gpio>;
		pinctrl-7 = <&pwm_config_as_gpio>;
		pwms = <&pmi8998_pwm_6 0 0>;
		qcom,boost-gpio = <&pm8998_gpios 7 0x00>;
		qcom,sleep-gpio = <&pmi8998_gpios 1 0>;
		qcom,sleep1-gpio = <&pmi8998_gpios 7 0>;
		qcom,dir-gpio = <&pmi8998_gpios 6 0>;
		qcom,enable-gpio = <&pmi8998_gpios 3 0>;
		qcom,step-gpio = <&pmi8998_gpios 8 0>;
		qcom,dir_switch-gpio = <&tlmm 129 0>;
	};

	proximity_power: proximity_power {
		compatible = "proximity_power";
		pinctrl-names = "power_gpio_low","power_gpio_high";
		pinctrl-0 = <&power_gpio_low>;
		pinctrl-1 = <&power_gpio_high>;
		qcom,power_gpio = <&tlmm 63 0>;
	};
};

/* Pinctrl */
&usb2_ext_5v_boost_default {
	pins = "gpio5";
};

&qupv3_se7_4uart_sleep {
	config {
		input-enable;
	};
};

&qupv3_se9_2uart_sleep {
	config {
		input-enable;
	};
};

&qupv3_se10_i2c_sleep {
	config {
		/delete-property/ bias-pull-up;
		input-enable;
		bias-no-pull;
	};
};

&tlmm {
	pmx_ts_int_active {
		ts_int_active: ts_int_active {
			mux {
				pins = "gpio125";
				function = "gpio";
			};

			config {
				pins = "gpio125";
				drive-strength = <8>;
				input-enable;
				bias-disable;
			};
		};
	};

	pmx_ts_reset_active {
		ts_reset_active: ts_reset_active {
			mux {
				pins = "gpio99";
				function = "gpio";
			};

			config {
				pins = "gpio99";
				drive-strength = <8>;
				bias-disable;
				output-low;
			};
		};
	};

	pmx_ts_1v8_active {
		ts_1v8_active: ts_1v8_active {
			mux {
				pins = "gpio32";
				function = "gpio";
			};

			config {
				pins = "gpio32";
				drive-strength = <8>;
				bias-disable;
			};
		};
	};
};

&qupv3_se9_2uart_sleep {
	config {
		input-enable;
	};
};

&qupv3_se11_i2c_active{
	mux {
		pins = "gpio32";
	};
	config {
		pins = "gpio32";
	};
};

&qupv3_se11_i2c_sleep{
	mux {
		pins = "gpio32";
	};
	config {
		pins = "gpio32";
	};
};

&qupv3_se11_spi_active{
	mux {
		pins = "gpio32", "gpio33", "gpio34";
	};
	config {
		pins = "gpio32", "gpio33", "gpio34";
	};
};

&qupv3_se11_spi_sleep{
	mux {
		pins = "gpio32", "gpio33", "gpio34";
	};
	config {
		pins = "gpio32", "gpio33", "gpio34";
	};
};

&qupv3_se14_spi_active{
	mux {
		pins = "gpio32", "gpio33", "gpio34";
	};
	config {
		pins = "gpio32", "gpio33", "gpio34";
	};
};

&qupv3_se14_spi_sleep{
	mux {
		pins = "gpio32", "gpio33", "gpio34";
	};
	config {
		pins = "gpio32", "gpio33", "gpio34";
	};
};

&qupv3_se9_i2c_active {
	mux {
		pins = "gpio6";
	};
	config {
		pins = "gpio6";
	};
};

&qupv3_se9_i2c_sleep {
	mux {
		pins = "gpio6";
	};
	config {
		pins = "gpio6";
	};
};

&qupv3_se9_spi_active {
	mux {
		pins = "gpio4", "gpio5", "gpio6";
	};
	config {
		pins = "gpio4", "gpio5", "gpio6";
	};
};

&qupv3_se9_spi_sleep {
	mux {
		pins = "gpio4", "gpio5", "gpio6";
	};
	config {
		pins = "gpio4", "gpio5", "gpio6";
	};
};

&tlmm {
	/delete-node/ pcie1;
};

&pm8998_gpios {
	/delete-node/ camera_rear_dvdd_en;

	charger {
		dischg_enable: dischg_enable {
			pins = "gpio19";
			function = "normal";
			power-source = <0>;
			output-high;
			input-disable;
		};

		dischg_disable: dischg_disable {
			pins = "gpio19";
			function = "normal";
			power-source = <0>;
			output-low;
			input-disable;
		};
	};
};

&tlmm {
	/delete-node/ pcie0;

	charger: charger {
		charging_switch1_active: charging_switch1_active {
			mux {
				pins = "gpio51";
				function = "gpio";
			};

			config {
				pins = "gpio51";
				drive-strength = <2>;
				bias-pull-up;
			};
		};

		charging_switch1_sleep: charging_switch1_sleep {
			mux {
				pins = "gpio51";
				function = "gpio";
			};

			config {
				pins = "gpio51";
				drive-strength = <2>;
				bias-pull-down;
			};
		};

		charging_reset_active: charging_reset_active {
			mux {
				pins = "gpio102";
				function = "gpio";
			};

			config {
				pins = "gpio102";
				drive-strength = <2>;
				bias-pull-up;
			};
		};

		charging_reset_sleep: charging_reset_sleep {
			mux {
				pins = "gpio102";
				function = "gpio";
			};

			config {
				pins = "gpio102";
				drive-strength = <2>;
				bias-pull-down;
			};
		};

		charging_clock_active: charging_clock_active {
			mux {
				pins = "gpio43";
				function = "gpio";
			};

			config {
				pins = "gpio43";
				drive-strength = <2>;
				bias-pull-up;
			};
		};

		charging_clock_sleep: charging_clock_sleep {
			mux {
				pins = "gpio43";
				function = "gpio";
			};

			config {
				pins = "gpio43";
				drive-strength = <2>;
				bias-pull-down;
			};
		};

		charging_data_active: charging_data_active {
			mux {
				pins = "gpio44";
				function = "gpio";
			};

			config {
				pins = "gpio44";
				drive-strength = <2>;
				bias-pull-up;
			};
		};

		charging_data_sleep: charging_data_sleep {
			mux {
				pins = "gpio44";
				function = "gpio";
			};

			config {
				pins = "gpio44";
				drive-strength = <2>;
				bias-pull-down;
			};
		};

		chargerid_switch_active: chargerid_switch_active {
			mux {
				pins = "gpio37";
				function = "gpio";
			};

			config {
				pins = "gpio37";
				drive-strength = <2>;
				bias-pull-up;
			};
		};

		chargerid_switch_sleep: chargerid_switch_sleep {
			mux {
				pins = "gpio37";
				function = "gpio";
			};

			config {
				pins = "gpio37";
				drive-strength = <2>;
				bias-pull-down;
			};
		};

		chargerid_switch_default: chargerid_switch_default {
			mux {
				pins = "gpio37";
				function = "gpio";
			};

			config {
				pins = "gpio37";
				drive-strength = <2>;
				bias-disable; /* NO PULL */
			};
		};

		ccdetect_active: ccdetect_active {
			mux {
				pins = "gpio31";
				function = "gpio";
			};

			config {
				pins = "gpio31";
				drive-strength = <2>;
				input-enable;
				// bias-pull-up; /* PULL UP */
				bias-disable;
			};
		};

		ccdetect_sleep: ccdetect_sleep {
			mux {
				pins = "gpio31";
				function = "gpio";
			};

			config {
				pins = "gpio31";
				drive-strength = <2>;
				// output-low;
				// bias-pull-down; /* PULL DOWN */
				input-enable;
				bias-disable;
			};
		};

		ship_sleep: ship_sleep {
			mux {
				pins = "gpio12";
				function = "gpio";
			};

			config {
				pins = "gpio12";
				drive-strength = <2>;
				bias-pull-down;
				output-low;
			};
		};

		ship_active: ship_active {
			mux {
				pins = "gpio12";
				function = "gpio";
			};

			config {
				pins = "gpio12";
				drive-strength = <2>;
				bias-pull-up;
				output-high;
			};
		};

		shortc_active: shortc_active {
			mux {
				pins = "gpio103";
				function = "gpio";
			};

			config {
				pins = "gpio103";
				drive-strength = <2>;
				input-enable;
				bias-pull-up; /* PULL UP */
			};
		};
	};
};

&tlmm {
	atest_usb13_active: atest_usb13_active {
		mux {
			pins = "gpio7";
			function = "gpio";
		};

		config {
			pins = "gpio7";
			drive-strength = <2>;
			bias-pull-up;
			output-high;
		};
	};

	atest_usb13_suspend: atest_usb13_suspend {
		mux {
			pins = "gpio7";
			function = "gpio";
		};

		config {
			pins = "gpio7";
			bias-pull-down;
			drive-strength = <2>;
			output-low;
		};
	};
};

&tlmm {
	qupv3_se9_2uart_outputlow: qupv3_se9_2uart_outputlow {
		mux {
			pins = "gpio4", "gpio5";
			function = "gpio";
		};

		config {
			pins = "gpio4", "gpio5";
			drive-strength = <2>;
			output-low;
		};
	};

	qupv3_se9_2uart_default: qupv3_se9_2uart_default {
		mux {
			pins = "gpio4", "gpio5";
			function = "gpio";
		};

		config {
			pins = "gpio4", "gpio5";
			drive-strength = <2>;
			bias-disable;
			input-enable;
		};
	};
};

&tlmm {
	qupv3_se10_i2c_pins: qupv3_se10_i2c_pins {
		qupv3_se10_i2c_pulldown: qupv3_se10_i2c_pulldown {
			mux {
				pins = "gpio55", "gpio56";
				function = "gpio";
			};

			config {
				pins = "gpio55", "gpio56";
				drive-strength = <2>;
				bias-pull-down;
				output-low;
			};
		};

		qupv3_se10_i2c_pullup: qupv3_se10_i2c_pullup {
			mux {
				pins = "gpio55", "gpio56";
				function = "gpio";
			};

			config {
				pins = "gpio55", "gpio56";
				drive-strength = <2>;
				bias-pull-up;
				input-enable;
			};
		};
	};
};

&tlmm {
	hw_sub_gpio_active: hw_sub_gpio_active {
		/* active state */
		mux {
			pins = "gpio24";
				function = "gpio";
			};
		config {
			pins = "gpio24";
			drive-strength = <2>; /* 2 MA */
			bias-pull-up;
		};
	};

	hw_sub_gpio_sleep: hw_sub_gpio_sleep {
		/* sleep state */
		mux {
			pins = "gpio24";
			function = "gpio";
		};
		config {
			pins = "gpio24";
			drive-strength = <2>; /* 2 MA */
			bias-pull-down; /* PULL DOWN */
		};
	};

	hw_version_active: hw_version_active {
		/* active state */
		mux {
			pins = "gpio116";
				function = "gpio";
			};
		config {
			pins = "gpio116";
			drive-strength = <2>; /* 2 MA */
			bias-pull-up;
		};
	};

	hw_version_sleep: hw_version_sleep {
		/* sleep state */
		mux {
			pins = "gpio116";
			function = "gpio";
		};
		config {
			pins = "gpio116";
			drive-strength = <2>; /* 2 MA */
			bias-pull-down; /* PULL DOWN */
		};
	};
};

&pm8998_gpios {
	/delete-node/ camera_rear_dvdd_en;
};

&tlmm {
	adnc_reset_active: adnc_reset_active {
		/* active state */
		mux {
			pins = "gpio25";
			function = "gpio";
		};
		config {
			pins = "gpio25";
			drive-strength = <2>; /* 2 MA */
			bias-pull-up;
			input-enable;
		};
	};

	adnc_reset_sleep: adnc_reset_sleep {
		/* sleep state */
		mux {
			pins = "gpio25";
			function = "gpio";
		};
		config {
			pins = "gpio25";
			drive-strength = <2>; /* 2 MA */
			input-enable;
			bias-pull-up;
		};
	};
};

&tlmm {
	wcd_usbc_switch_en1 {
		wcd_usbc_switch_en1_idle: wcd_usbc_ana_en1_idle {
			mux {
				pins = "gpio104";
				function = "gpio";
			};
			config {
				pins = "gpio104";
				drive-strength = <2>;
				bias-pull-down;
				output-low;
			};
		};

		wcd_usbc_switch_en1_active: wcd_usbc_ana_en1_active {
			mux {
				pins = "gpio104";
				function = "gpio";
			};
			config {
				pins = "gpio104";
				drive-strength = <2>;
				bias-pull-up;
				output-high;
			};
		};
	};
};

&tlmm {
	mdss_vci_pin_active: mdss_vci_pin_active {
		mux {
			pins = "gpio26";
			function = "gpio";
		};
		config {
			pins = "gpio26";
			drive-strength = <2>; /* 2 mA */
			bias-pull-up;
		};
	};

	mdss_vci_pin_suspend: mdss_vci_pin_suspend {
		mux {
			pins = "gpio26";
			function = "gpio";
		};
		config {
			pins = "gpio26";
			drive-strength = <2>; /* 2 mA */
			bias-disable;
		};
	};
};

&pm8998_gpios {
	key_vol_down {
		key_vol_down_default: key_vol_down_default {
			pins = "gpio5";
			function = "normal";
			input-enable;
			bias-pull-up;
			power-source = <0>;
		};
	};
};

&tlmm {
	dir_switch_gpio_input_high: dir_switch_gpio_input_high {
		mux {
			pins = "gpio129";
			function = "gpio";
		};

		config {
			pins = "gpio129";
			drive-strength = <2>;
			input-enable;
			bias-pull-up;
		};
	};

	dir_switch_gpio_input_low: dir_switch_gpio_input_low {
		mux {
			pins = "gpio129";
			function = "gpio";
		};
		config {
			pins = "gpio129";
			drive-strength = <2>;
			input-enable;
			bias-pull-down;
		};
	};

	hall_power_up: hall_power_up {
		mux {
			pins = "gpio21";
			function = "gpio";
		};

		config {
			pins = "gpio21";
			drive-strength = <2>;
			output-high;
			bias-pull-down;
		};
	};

	hall_power_down: hall_power_down {
		mux {
			pins = "gpio21";
			function = "gpio";
		};
		config {
			pins = "gpio21";
			drive-strength = <2>;
			output-low;
			bias-pull-down;
		};
	};

	free_fall_input: free_fall_input {
		mux {
			pins = "gpio120";
			function = "gpio";
		};

		config {
			pins = "gpio120";
			drive-strength = <2>;
			input-enable;
			bias-disable; // No Pull
		};
	};
	hall0_interrupt_input: hall0_interrupt_input {
		mux {
			pins = "gpio124";
			function = "gpio";
		};
		config {
			pins = "gpio124";
			drive-strength = <2>;
			input-enable;
			bias-disable; // No Pull
		};
	};
	hall1_interrupt_input: hall1_interrupt_input {
		mux {
			pins = "gpio92";
			function = "gpio";
		};
		config {
			pins = "gpio92";
			drive-strength = <2>;
			input-enable;
			bias-disable; // No Pull
		};
	};
	power_gpio_high: power_gpio_high {
		mux {
			pins = "gpio63";
			function = "gpio";
		};
		config {
			pins = "gpio63";
			drive-strength = <2>;
			output-high;
			bias-disable; // No Pull
		};
	};
	power_gpio_low: power_gpio_low {
		mux {
			pins = "gpio63";
			function = "gpio";
		};

		config {
			pins = "gpio63";
			drive-strength = <2>;
			output-low;
			bias-disable; // No Pull
		};
	};
};

&tlmm {
	/delete-node/ pcie1;
	/delete-node/ qupv3_se2_i2c_pins;
	/delete-node/ qupv3_se2_spi_pins;
	/delete-node/ cam_sensor_rear_vana;
	/delete-node/ sec_aux_pcm_din;
	/delete-node/ sec_mi2s_sd0;
	/delete-node/ qupv3_se15_i2c_pins;
	/delete-node/ qupv3_se15_spi_pins;

	cam_res_mgr_active: cam_res_mgr_active {
		mux {
			pins = "gpio122";
		};

		config {
			pins = "gpio122";
		};
	};

	cam_sensor_rear_vana: cam_sensor_rear_vana {
		/* AVDD LDO */
		mux {
			pins = "gpio27";
			function = "gpio";
		};

		config {
			pins = "gpio27";
			bias-disable; /* No PULL */
			drive-strength = <2>; /* 2 MA */
		};
	};

	cam_res_mgr_suspend: cam_res_mgr_suspend {
		mux {
			pins = "gpio122","gpio8";
		};

		config {
			pins = "gpio122";
		};
	};

	cam_sensor_rear_active: cam_sensor_rear_active {
		mux {
			pins = "gpio28";
			function = "gpio";
		};

		config {
			pins = "gpio28";
			bias-disable; /* No PULL */
			drive-strength = <2>; /* 2 MA */
		};
	};

	cam_sensor_rear_suspend: cam_sensor_rear_suspend {
		mux {
			pins = "gpio28";
			function = "gpio";
		};

		config {
			pins = "gpio28";
			bias-pull-down; /* PULL DOWN */
			drive-strength = <2>; /* 2 MA */
			output-low;
		};
	};

	cam_sensor_front_active: cam_sensor_front_active {
		mux {
			pins = "gpio9","gpio117";
			function = "gpio";
		};

		config {
			pins = "gpio9","gpio117";
			bias-disable; /* No PULL */
			drive-strength = <2>; /* 2 MA */
		};
	};

	cam_sensor_front_suspend: cam_sensor_front_suspend {
		mux {
			pins = "gpio9","gpio117";
			function = "gpio";
		};

		config {
			pins = "gpio9","gpio117";
			bias-pull-down; /* PULL DOWN */
			drive-strength = <2>; /* 2 MA */
			output-low;
		};
	};

	cam_sensor_rear2_active: cam_sensor_rear2_active {
		mux {
			pins = "gpio23","gpio82","gpio79";
			function = "gpio";
		};

		config {
			pins = "gpio23","gpio82","gpio79";
			bias-disable; /* No PULL */
			drive-strength = <2>; /* 2 MA */
		};
	};

	cam_sensor_rear2_suspend: cam_sensor_rear2_suspend {
		mux {
			pins = "gpio23","gpio82","gpio79";
			function = "gpio";
		};
		config {
			pins = "gpio23","gpio82","gpio79";
			bias-pull-down; /* PULL DOWN */
			drive-strength = <2>; /* 2 MA */
			output-low;
		};
	};
};

/* Regulator */
&pm8998_l28 {
	regulator-max-microvolt = <3300000>;
};

&pmi8998_bob {
	regulator-max-microvolt = <3900000>;
};

&pmi8998_bob_ao {
	regulator-max-microvolt = <3900000>;
};

/*
 * OPLUS port note: the OPPO additions below originally lived in
 * sdm845-mtp.dtsi (import commit 6e9980f6fec8), which broke standalone
 * sdm845-mtp.dtb builds (key_vol_down_default / hw_version_* labels only
 * exist in this file). Moved here; DT node-merge semantics override the
 * generic mtp gpio_keys for Find X (17107/17127) only.
 */
&soc {
        gpio_keys {
                pinctrl-names = "default";
                pinctrl-0 = <&key_vol_up_default
                             &key_vol_down_default>;

                /delete-node/ cam_snapshot;
                /delete-node/ cam_focus;

                vol_down {
                        label = "volume_down";
                        gpios = <&pm8998_gpios 5 GPIO_ACTIVE_LOW>;
                        linux,input-type = <1>;
                        linux,code = <114>;
                        gpio-key,wakeup;
                        debounce-interval = <15>;
                        linux,can-disable;
                };

                devinfo {
                        compatible = "oppo-devinfo";
                        Hw,sub_hwid_1 = <&tlmm 24 0x00>;
                        Hw,high_version = <&tlmm 116 0x00>;
                        pinctrl-names = "default","hw_sub_gpio_sleep", "high_version_active", "high_version_sleep";
                        pinctrl-0 = <&hw_sub_gpio_active>;
                        pinctrl-1 = <&hw_sub_gpio_sleep>;
                        pinctrl-2 = <&hw_version_active>;
                        pinctrl-3 = <&hw_version_sleep>;
                };
        };
};
